# PIC32CM2532LE00100 device description
Architecture: CORTEX-M23; Family: PIC32CM; Series: PIC32CMLE00
Registers are 32-bit, read-write, reset 0x0 unless marked. A register's access mark holds for its fields unless they carry their own. Offsets are from the block's base; [hi:lo] are bit positions; {n}, {i} and the like mark numbered series; 'fields as' and 'values as' point back to an identical list.

## USER_FUSES — Non-Volatile Fuses
Instances: USER_FUSES 0x00804000 in fuses
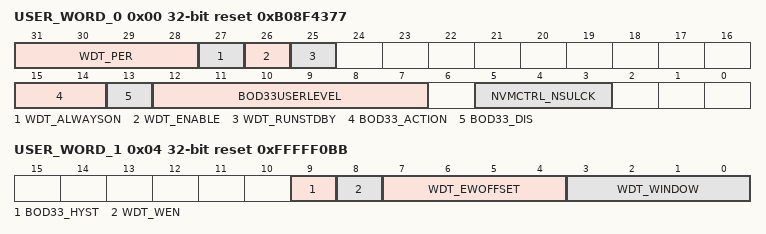
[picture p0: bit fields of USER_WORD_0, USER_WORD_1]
0x00 USER_WORD_0 reset 0xB08F4377 — USER Page Word 0
  [31:28] WDT_PER — WDT Period
  [27] WDT_ALWAYSON
  [26] WDT_ENABLE
  [25] WDT_RUNSTDBY — WDT Run During Standby
  [15:14] BOD33_ACTION
  [13] BOD33_DIS — BOD33 Disable
  [12:7] BOD33USERLEVEL
  [5:3] NVMCTRL_NSULCK — NVM Non-Secure Region Locks
0x04 USER_WORD_1 reset 0xFFFFF0BB — USER Page Word 1
  [9] BOD33_HYST — BOD33 Hysteresis
  [8] WDT_WEN — WDT Window Mode Enable
  [7:4] WDT_EWOFFSET — WDT Early Warning Offset
  [3:0] WDT_WINDOW
0x0C USER_WORD_3 reset 0xFFFFFFFF — USER Page Word 3
  [10] NVMCTRL_URWEN — User Row Write Enable

## OSC32KCTRL — 32k Oscillators Control
Instances: OSC32KCTRL 0x40001400
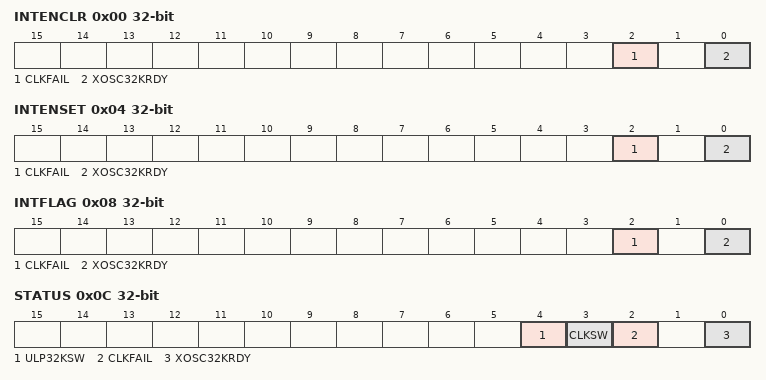
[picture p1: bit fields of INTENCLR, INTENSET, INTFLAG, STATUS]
0x00 INTENCLR (atomic clear) — Interrupt Enable Clear
  [2] CLKFAIL — XOSC32K Clock Failure Detector Interrupt Enable
  [0] XOSC32KRDY — XOSC32K Ready Interrupt Enable
0x04 INTENSET (atomic set) — Interrupt Enable Set
  fields as INTENCLR
0x08 INTFLAG (atomic clear) — Interrupt Flag Status and Clear
  [2] CLKFAIL — XOSC32K Clock Failure Detector
  [0] XOSC32KRDY — XOSC32K Ready
0x0C STATUS ro — Power and Clocks Status
  [4] ULP32KSW — OSCULP32K Clock Switch
  [3] CLKSW — XOSC32K Clock switch
  [2] CLKFAIL — XOSC32K Clock Failure Detector
  [0] XOSC32KRDY — XOSC32K Ready
0x10 RTCCTRL 8-bit — RTC Clock Selection
  [2:0] RTCSEL
    0=ULP1K (1.024kHz from 32kHz internal ULP oscillator); 1=ULP32K (32.768kHz from 32kHz internal ULP oscillator); 4=XOSC1K (1.024kHz from 32.768kHz external crystal oscillator); 5=XOSC32K (32.768kHz from 32.768kHz external crystal oscillator)
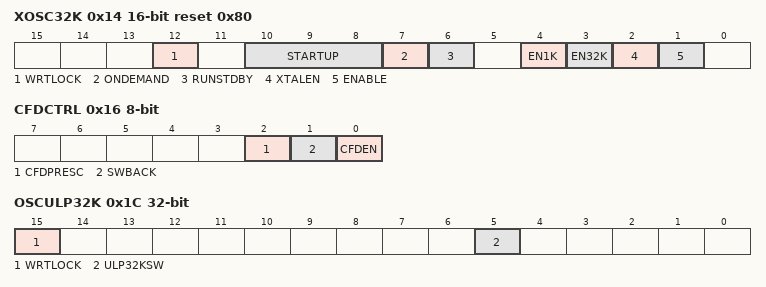
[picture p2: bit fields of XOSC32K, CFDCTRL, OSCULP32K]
0x14 XOSC32K 16-bit reset 0x80 — 32kHz External Crystal Oscillator (XOSC32K) Control
  [12] WRTLOCK — Write Lock
  [10:8] STARTUP — Oscillator Start-Up Time
    0=CYCLE2048 (62.5 ms); 1=CYCLE4096 (125 ms); 2=CYCLE16384 (500 ms); 3=CYCLE32768 (1000 ms); 4=CYCLE65536 (2000 ms); 5=CYCLE131072 (4000 ms); 6=CYCLE262144 (8000 ms)
  [7] ONDEMAND — On Demand Control
  [6] RUNSTDBY — Run in Standby
  [4] EN1K — 1kHz Output Enable
  [3] EN32K — 32kHz Output Enable
  [2] XTALEN — Crystal Oscillator Enable
  [1] ENABLE — Oscillator Enable
0x16 CFDCTRL 8-bit — Clock Failure Detector Control
  [2] CFDPRESC — Clock Failure Detector Prescaler
  [1] SWBACK — Clock Switch Back Enable
  [0] CFDEN — Clock Failure Detector Enable
0x17 EVCTRL 8-bit — Event Control
  [0] CFDEO — Clock Failure Detector Event Output Enable
0x1C OSCULP32K — 32kHz Ultra Low Power Internal Oscillator (OSCULP32K) Control
  [15] WRTLOCK — Write Lock
  [5] ULP32KSW — OSCULP32K Clock Switch Enable

## PAC — Peripheral Access Controller
Instances: PAC 0x40000000
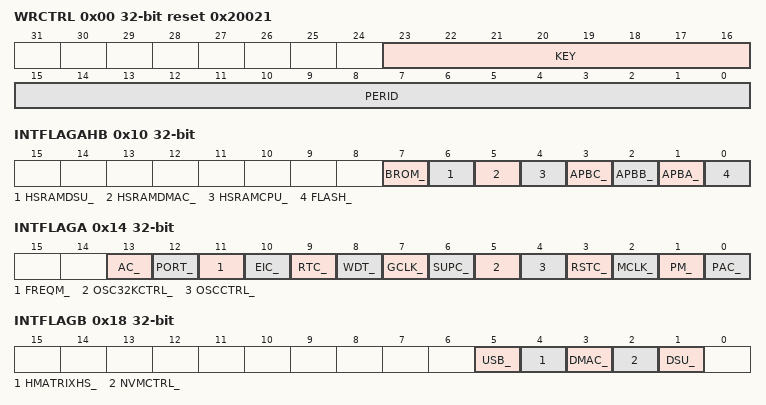
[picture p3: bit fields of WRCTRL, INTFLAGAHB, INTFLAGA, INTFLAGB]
0x00 WRCTRL reset 0x20021 — Write control
  [23:16] KEY — Peripheral access control key
    0=OFF (No action); 1=CLR (Clear protection); 2=SET (Set protection); 3=SETLCK (Set and lock protection)
  [15:0] PERID — Peripheral identifier
0x04 EVCTRL 8-bit — Event control
  [0] ERREO — Peripheral acess error event output
0x08 INTENCLR 8-bit (atomic clear) — Interrupt enable clear
  [0] ERR — Peripheral access error interrupt disable
0x09 INTENSET 8-bit (atomic set) — Interrupt enable set
  [0] ERR — Peripheral access error interrupt enable
0x10 INTFLAGAHB (atomic clear) — Bridge interrupt flag status
  [7] BROM_, [6] HSRAMDSU_, [5] HSRAMDMAC_, [4] HSRAMCPU_, [3] APBC_, [2] APBB_, [1] APBA_, [0] FLASH_
0x14 INTFLAGA (atomic clear) — Peripheral interrupt flag status - Bridge A
  [13] AC_, [12] PORT_, [11] FREQM_, [10] EIC_, [9] RTC_, [8] WDT_, [7] GCLK_, [6] SUPC_, [5] OSC32KCTRL_, [4] OSCCTRL_, [3] RSTC_, [2] MCLK_, [1] PM_, [0] PAC_
0x18 INTFLAGB (atomic clear) — Peripheral interrupt flag status - Bridge B
  [5] USB_, [4] HMATRIXHS_, [3] DMAC_, [2] NVMCTRL_, [1] DSU_
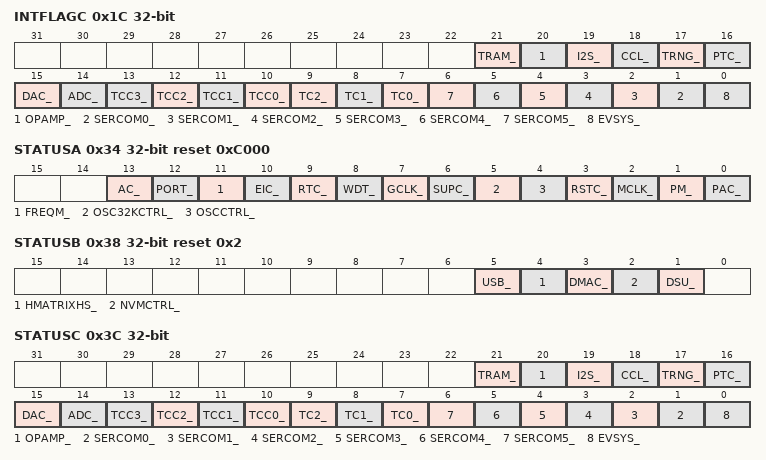
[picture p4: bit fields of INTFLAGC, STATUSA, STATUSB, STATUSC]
0x1C INTFLAGC (atomic clear) — Peripheral interrupt flag status - Bridge C
  [21] TRAM_, [20] OPAMP_, [19] I2S_, [18] CCL_, [17] TRNG_, [16] PTC_, [15] DAC_, [14] ADC_, [n+10] TCC{n}_ (n=0..3), [9] TC2_, [8] TC1_, [7] TC0_, [n+1] SERCOM{n}_ (n=0..5), [0] EVSYS_
0x34 STATUSA ro reset 0xC000 — Peripheral write protection status - Bridge A
  [13] AC_ — AC APB Protect Enable
  [12] PORT_ — PORT APB Protect Enable
  [11] FREQM_ — FREQM APB Protect Enable
  [10] EIC_ — EIC APB Protect Enable
  [9] RTC_ — RTC APB Protect Enable
  [8] WDT_ — WDT APB Protect Enable
  [7] GCLK_ — GCLK APB Protect Enable
  [6] SUPC_ — SUPC APB Protect Enable
  [5] OSC32KCTRL_ — OSC32KCTRL APB Protect Enable
  [4] OSCCTRL_ — OSCCTRL APB Protect Enable
  [3] RSTC_ — RSTC APB Protect Enable
  [2] MCLK_ — MCLK APB Protect Enable
  [1] PM_ — PM APB Protect Enable
  [0] PAC_ — PAC APB Protect Enable
0x38 STATUSB ro reset 0x2 — Peripheral write protection status - Bridge B
  [5] USB_ — USB APB Protect Enable
  [4] HMATRIXHS_ — HMATRIXHS APB Protect Enable
  [3] DMAC_ — DMAC APB Protect Enable
  [2] NVMCTRL_ — NVMCTRL APB Protect Enable
  [1] DSU_ — DSU APB Protect Enable
0x3C STATUSC ro — Peripheral write protection status - Bridge C
  [21] TRAM_ — TRAM APB Protect Enable
  [20] OPAMP_ — OPAMP APB Protect Enable
  [19] I2S_ — I2S APB Protect Enable
  [18] CCL_ — CCL APB Protect Enable
  [17] TRNG_ — TRNG APB Protect Enable
  [16] PTC_ — PTC APB Protect Enable
  [15] DAC_ — DAC APB Protect Enable
  [14] ADC_ — ADC APB Protect Enable
  [n+10] TCC{n}_ (n=0..3) — TCC{n} APB Protect Enable
  [9] TC2_ — TC2 APB Protect Enable
  [8] TC1_ — TC1 APB Protect Enable
  [7] TC0_ — TC0 APB Protect Enable
  [n+1] SERCOM{n}_ (n=0..5) — SERCOM{n} APB Protect Enable
  [0] EVSYS_ — EVSYS APB Protect Enable

## Notices in the file
Copyright (c) 2019 Microchip Technology Inc.
SPDX-License-Identifier: Apache-2.0
Licensed under the Apache License, Version 2.0 (the "License");
you may not use this file except in compliance with the License.
You may obtain a copy of the License at
http://www.apache.org/licenses/LICENSE-2.0
Unless required by applicable law or agreed to in writing, software
distributed under the License is distributed on an "AS IS" BASIS,
WITHOUT WARRANTIES OR CONDITIONS OF ANY KIND, either express or implied.
See the License for the specific language governing permissions and
limitations under the License.
